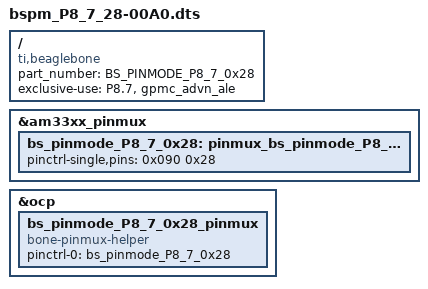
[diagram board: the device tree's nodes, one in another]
/*
 * This is a template-generated file from BoneScript
 */

/dts-v1/;
/plugin/;

/{
    compatible = "ti,beaglebone", "ti,beaglebone-black";
    part_number = "BS_PINMODE_P8_7_0x28";

    exclusive-use =
        "P8.7",
        "gpmc_advn_ale";

    fragment@0 {
        target = <&am33xx_pinmux>;
        __overlay__ {
            bs_pinmode_P8_7_0x28: pinmux_bs_pinmode_P8_7_0x28 {
                pinctrl-single,pins = <0x090 0x28>;
            };
        };
    };

    fragment@1 {
        target = <&ocp>;
        __overlay__ {
            bs_pinmode_P8_7_0x28_pinmux {
                compatible = "bone-pinmux-helper";
                status = "okay";
                pinctrl-names = "default";
                pinctrl-0 = <&bs_pinmode_P8_7_0x28>;
            };
        };
    };
};
